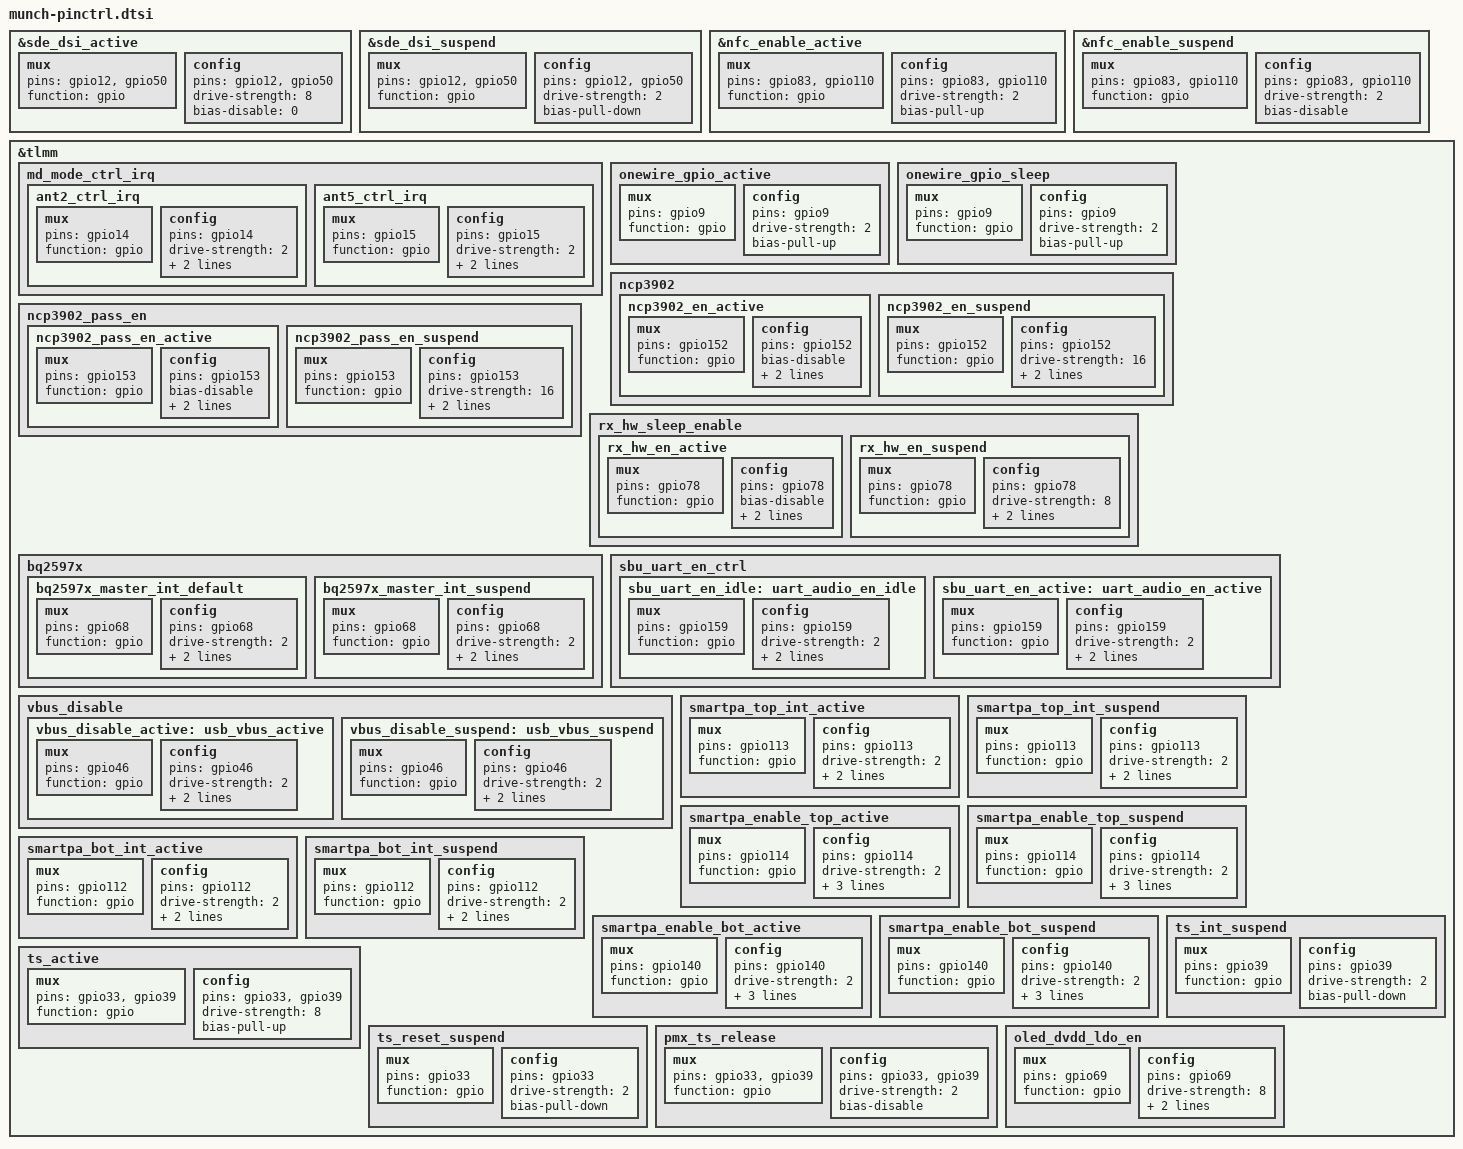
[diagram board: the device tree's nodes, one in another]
/*for L11R pinctrl */

&sde_dsi_active {
	mux {
		pins = "gpio12", "gpio50";
		function = "gpio";
	};

	config {
		pins = "gpio12", "gpio50";
		drive-strength = <8>;	/* 8 mA */
		bias-disable = <0>;   /* no pull */
	};
};

&sde_dsi_suspend {
	mux {
		pins = "gpio12", "gpio50";
		function = "gpio";
	};

	config {
		pins = "gpio12", "gpio50";
		drive-strength = <2>;	/* 2 mA */
		bias-pull-down; 		/* PULL DOWN */
	};
};

&nfc_enable_active {
	/* active state */
	mux {
		/* 83: Enable 110: Firmware */
		pins = "gpio83", "gpio110";
		function = "gpio";
	};

	config {
		pins = "gpio83", "gpio110";
		drive-strength = <2>; /* 2 MA */
		bias-pull-up;
	};
};

&nfc_enable_suspend {
	/* sleep state */
	mux {
		/* 83: Enable 110: Firmware */
		pins = "gpio83", "gpio110";
		function = "gpio";
	};

	config {
		pins = "gpio83", "gpio110";
		drive-strength = <2>; /* 2 MA */
		bias-disable;
	};
};


&tlmm {
         md_mode_ctrl_irq {
		ant2_ctrl_irq: ant2_ctrl_irq {
			mux {
				pins = "gpio14";
				function = "gpio";
			};

			config {
				pins = "gpio14";
				drive-strength = <2>;
				bias-disable;
				input-enable;
			};
		};

		ant5_ctrl_irq: ant5_ctrl_irq {
			mux {
				pins = "gpio15";
				function = "gpio";
			};

			config {
				pins = "gpio15";
				drive-strength = <2>;
				bias-disable;
				input-enable;
			};
                };
	};

	onewire_gpio_active: onewire_gpio_active {
		mux {
			pins = "gpio9";
			function = "gpio";
		};

		config {
			pins = "gpio9";
			drive-strength = <2>;
			bias-pull-up; /* No PULL */
		};
	};

	onewire_gpio_sleep: onewire_gpio_sleep {
		mux {
			pins = "gpio9";
			function = "gpio";
		};

		config {
			pins = "gpio9";
			drive-strength = <2>;
			bias-pull-up; /* No PULL */
		};
	};

	/* used for wire charging and otg and wirelss reverse charging features */
	ncp3902 {
		ncp3902_en_active: ncp3902_en_active {
			/* active state */
			mux {
				/* GPIO 152 is used for NCP3092 chip to enable */
				pins = "gpio152";
				function = "gpio";
			};

			config {
				pins = "gpio152";
				bias-disable; /* No PULL */
				drive-strength = <16>; /* 16 MA */
				output-low;
			};
		};

		ncp3902_en_suspend: ncp3902_en_suspend {
			/* sleep state */
			mux {
				pins = "gpio152";
				function = "gpio";
			};

			config {
				pins = "gpio152";
				drive-strength = <16>; /* 16 MA */
				bias-disable;
				output-low;
			};
		};
	};

	ncp3902_pass_en {
		ncp3902_pass_en_active: ncp3902_pass_en_active {
			/* active state */
			mux {
				pins = "gpio153";
				function = "gpio";
			};

			config {
				pins = "gpio153";
				bias-disable; /* No PULL */
				drive-strength = <16>; /* 16 MA */
				output-low;
			};
		};

		ncp3902_pass_en_suspend: ncp3902_pass_en_suspend {
			/* sleep state */
			mux {
				pins = "gpio153";
				function = "gpio";
			};

			config {
				pins = "gpio153";
				drive-strength = <16>; /* 16 MA */
				bias-disable;
				output-low;
			};
		};
	};
	rx_hw_sleep_enable {
		rx_hw_en_active: rx_hw_en_active {
			/* active state */
			mux {
				/* GPIO 78 is used for hardware disable wireless rx */
				pins = "gpio78";
				function = "gpio";
			};

			config {
				pins = "gpio78";
				bias-disable; /* No PULL */
				drive-strength = <8>; /* 8 MA */
				output-high;
			};
		};

		rx_hw_en_suspend: rx_hw_en_suspend {
			/* sleep state */
			mux {
				pins = "gpio78";
				function = "gpio";
			};

			config {
				pins = "gpio78";
				drive-strength = <8>; /* 8 MA */
				bias-disable;
				output-low;
			};
		};
	};

	bq2597x {
		bq2597x_master_int_default: bq2597x_master_int_default {
			/* active state */
			mux {
				/* GPIO 68 is used for bq25970 master ic interrupt usage */
				pins = "gpio68";
				function = "gpio";
			};

			config {
				pins = "gpio68";
				drive-strength = <2>; /* 2 MA */
				bias-pull-up;
				input-enable;
			};
		};

		bq2597x_master_int_suspend: bq2597x_master_int_suspend {
			/* sleep state */
			mux {
				/* GPIO 68 is used for bq25970 master ic interrupt usage */
				pins = "gpio68";
				function = "gpio";
			};

			config {
				pins = "gpio68";
				drive-strength = <2>; /* 2 MA */
				bias-pull-up;
				input-enable;
			};
		};
	};

	sbu_uart_en_ctrl {
		sbu_uart_en_idle: uart_audio_en_idle {
			mux {
				pins = "gpio159";
				function = "gpio";
			};
			config {
				pins = "gpio159";
				drive-strength = <2>;
				bias-pull-down;
				output-low;
			};
		};

		sbu_uart_en_active: uart_audio_en_active {
			mux {
				pins = "gpio159";
				function = "gpio";
			};
			config {
				pins = "gpio159";
				drive-strength = <2>;
				bias-disable;
				output-high;
			};
		};
	};

	vbus_disable {
		vbus_disable_active: usb_vbus_active {
			/* active state */
			mux {
				pins = "gpio46";
				function = "gpio";
			};

			config {
				pins = "gpio46";
				drive-strength = <2>; /* 2 MA */
				bias-pull-up;
				output-high;
			};
		};

		vbus_disable_suspend: usb_vbus_suspend {
			mux {
				pins = "gpio46";
				function = "gpio";
			};

			config {
				pins = "gpio46";
				drive-strength = <2>; /* 2 MA */
				bias-pull-down;
				output-low;
			};
		};
	};

	smartpa_top_int_active: smartpa_top_int_active {
		/* active state */
		mux {
		/* GPIO 113 Interrupt */
			pins = "gpio113";
			function = "gpio";
		};

		config {
			pins = "gpio113";
			drive-strength = <2>; /* 2 MA */
			bias-pull-up;
			input-enable;
		};
	};

	smartpa_top_int_suspend: smartpa_top_int_suspend {
		/* sleep state */
		mux {
		/* GPIO 113 Interrupt */
			pins = "gpio113";
			function = "gpio";
		};

		config {
			pins = "gpio113";
			drive-strength = <2>; /* 2 MA */
			bias-pull-up;
			input-enable;
		};
	};

	smartpa_enable_top_active: smartpa_enable_top_active {
		/* active state */
		mux {
		/* GPIO 114 rst pin */
			pins = "gpio114";
			function = "gpio";
		};

		config {
			pins = "gpio114";
			drive-strength = <2>;
			bias-disable;
			bias-pull-down;
			output-low;
		};
	};

	smartpa_enable_top_suspend: smartpa_enable_top_suspend {
		/* sleep state */
		mux {
			/* GPIO 114 rst pin */
			pins = "gpio114";
			function = "gpio";
		};

		config {
			pins = "gpio114";
			drive-strength = <2>;
			bias-disable;
			bias-pull-down;
			output-low;
		};
	};

	/* speaker switch spk-sw-gpio = <&tlmm 24 0>;
	spk_sw_active: spk_sw_active {
		mux {
			pins = "gpio24";
			function = "gpio";
		};

		config {
			pins = "gpio24";
			drive-strength = <2>;
			bias-disable;
			bias-pull-down;
			output-low;
		};
	};

	spk_sw_inactive: spk_sw_inactive {
		mux {
			pins = "gpio24";
			function = "gpio";
		};

		config {
			pins = "gpio24";
			drive-strength = <2>;
			bias-disable;
			bias-pull-down;
			output-low;
		};
	};*/

	smartpa_bot_int_active: smartpa_bot_int_active {
		/* active state */
		mux {
		/* GPIO 112 Interrupt */
			pins = "gpio112";
			function = "gpio";
		};

		config {
			pins = "gpio112";
			drive-strength = <2>; /* 2 MA */
			bias-pull-up;
			input-enable;
		};
	};

	smartpa_bot_int_suspend: smartpa_bot_int_suspend {
		/* sleep state */
		mux {
		/* GPIO 112 Interrupt */
			pins = "gpio112";
			function = "gpio";
		};

		config {
			pins = "gpio112";
			drive-strength = <2>; /* 2 MA */
			bias-pull-up;
			input-enable;
		};
	};

	smartpa_enable_bot_active: smartpa_enable_bot_active {
		/* active state */
		mux {
		/* GPIO 140 rst pin */
			pins = "gpio140";
			function = "gpio";
		};

		config {
			pins = "gpio140";
			drive-strength = <2>;
			bias-disable;
			bias-pull-down;
			output-low;
		};
	};

	smartpa_enable_bot_suspend: smartpa_enable_bot_suspend {
		/* sleep state */
		mux {
			/* GPIO 140 rst pin */
			pins = "gpio140";
			function = "gpio";
		};

		config {
			pins = "gpio140";
			drive-strength = <2>;
			bias-disable;
			bias-pull-down;
			output-low;
		};
	};

	/*touch node*/
	ts_active: ts_active {
		mux {
			pins = "gpio33", "gpio39";
			function = "gpio";
		};

		config {
			pins = "gpio33", "gpio39";
			drive-strength = <8>;
			bias-pull-up;
		};
	};

	ts_int_suspend: ts_int_suspend{
		mux {
			pins = "gpio39";
			function = "gpio";
		};

		config {
			pins = "gpio39";
			drive-strength = <2>;
			bias-pull-down;
		};
	};

	ts_reset_suspend: ts_reset_suspend{
		mux {
			pins = "gpio33";
			function = "gpio";
		};

		config {
			pins = "gpio33";
			drive-strength = <2>;
			bias-pull-down;
		};
	};

	pmx_ts_release: pmx_ts_release{
		mux {
			pins = "gpio33", "gpio39";
			function = "gpio";
		};

		config {
			pins = "gpio33", "gpio39";
			drive-strength = <2>;
			bias-disable;
		};
	};

	/* GPIO_69 : oled_dvdd_ldo +1.2.V */
	oled_dvdd_ldo_en: oled_dvdd_ldo_en {
		mux {
			pins = "gpio69";
			function = "gpio";
		};

		config {
			pins = "gpio69";
			drive-strength = <8>;
			bias-disable = <0>;
			output-high;
		};
	};
};
